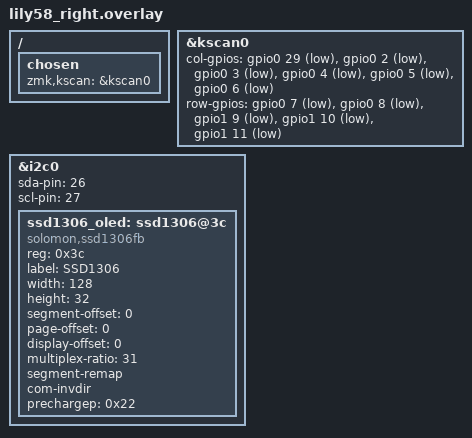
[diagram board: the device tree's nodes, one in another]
/ {
    chosen {
        zmk,kscan = &kscan0;
    };
};

&kscan0 {
    col-gpios = <&gpio0 29 GPIO_ACTIVE_LOW>,
                <&gpio0 2 GPIO_ACTIVE_LOW>,
                <&gpio0 3 GPIO_ACTIVE_LOW>,
                <&gpio0 4 GPIO_ACTIVE_LOW>,
                <&gpio0 5 GPIO_ACTIVE_LOW>,
                <&gpio0 6 GPIO_ACTIVE_LOW>;
    row-gpios = <&gpio0 7 GPIO_ACTIVE_LOW>,
                <&gpio0 8 GPIO_ACTIVE_LOW>,
                <&gpio1 9 GPIO_ACTIVE_LOW>,
                <&gpio1 10 GPIO_ACTIVE_LOW>,
                <&gpio1 11 GPIO_ACTIVE_LOW>;
};
&i2c0 {
    status = "okay";
    sda-pin = <26>;
    scl-pin = <27>;

    ssd1306_oled: ssd1306@3c {
        compatible = "solomon,ssd1306fb";
        reg = <0x3c>;
        label = "SSD1306";
        width = <128>;
        height = <32>;
        segment-offset = <0>;
        page-offset = <0>;
        display-offset = <0>;
        multiplex-ratio = <31>;
        segment-remap;
        com-invdir;
        prechargep = <0x22>;
    };
};
